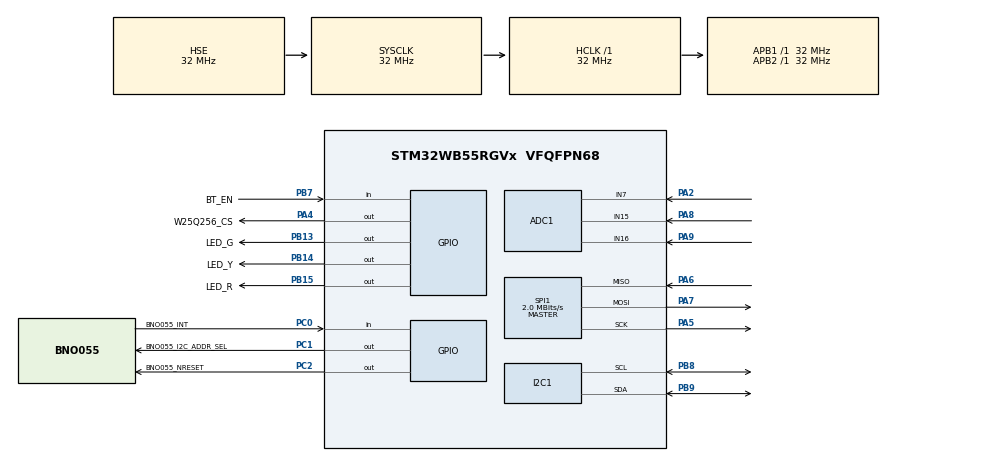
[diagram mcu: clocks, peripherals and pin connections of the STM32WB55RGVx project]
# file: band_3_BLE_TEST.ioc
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ADC1.Channel-2\#ChannelRegularConversion=ADC_CHANNEL_7
ADC1.NbrOfConversionFlag=1
ADC1.OffsetNumber-2\#ChannelRegularConversion=ADC_OFFSET_NONE
ADC1.Rank-2\#ChannelRegularConversion=1
ADC1.SamplingTime-2\#ChannelRegularConversion=ADC_SAMPLETIME_2CYCLES_5
ADC1.master=1
I2C1.Timing=0x00B07CB4
Mcu.Family=STM32WB
Mcu.Name=STM32WB55RGVx
Mcu.Package=VFQFPN68
NVIC.HSEM_IRQn=true\:0\:0\:false\:false\:true\:false\:true\:true
NVIC.IPCC_C1_RX_IRQn=true\:0\:0\:false\:false\:true\:true\:true\:true
NVIC.IPCC_C1_TX_IRQn=true\:0\:0\:false\:false\:true\:true\:true\:true
NVIC.PriorityGroup=NVIC_PRIORITYGROUP_4
NVIC.RTC_WKUP_IRQn=true\:0\:0\:false\:false\:true\:true\:true\:true
OSC_IN.Mode=HSE-External-Oscillator
OSC_IN.Signal=RCC_OSC_IN
OSC_OUT.Mode=HSE-External-Oscillator
OSC_OUT.Signal=RCC_OSC_OUT
PA11.Signal=USB_DM
PA12.Signal=USB_DP
PA13.Mode=Serial_Wire
PA13.Signal=SYS_JTMS-SWDIO
PA14.Mode=Serial_Wire
PA14.Signal=SYS_JTCK-SWCLK
PA2.Signal=ADCx_IN7
PA3.Signal=ADCx_IN8
PA4.GPIO_Label=W25Q256_CS
PA4.GPIO_Speed=GPIO_SPEED_FREQ_LOW
PA4.PinState=GPIO_PIN_SET
PA4.Signal=GPIO_Output
PA5.Mode=Full_Duplex_Master
PA5.Signal=SPI1_SCK
PA6.Mode=Full_Duplex_Master
PA6.Signal=SPI1_MISO
PA7.Mode=Full_Duplex_Master
PA7.Signal=SPI1_MOSI
PA8.Signal=ADCx_IN15
PA9.Signal=ADCx_IN16
PB13.GPIO_Label=LED_G
PB13.GPIO_Speed=GPIO_SPEED_FREQ_HIGH
PB13.PinState=GPIO_PIN_RESET
PB13.Signal=GPIO_Output
PB14.GPIO_Label=LED_Y
PB14.GPIO_Speed=GPIO_SPEED_FREQ_HIGH
PB14.PinState=GPIO_PIN_RESET
PB14.Signal=GPIO_Output
PB15.GPIO_Label=LED_R
PB15.GPIO_Speed=GPIO_SPEED_FREQ_HIGH
PB15.PinState=GPIO_PIN_SET
PB15.Signal=GPIO_Output
PB7.GPIO_Label=BT_EN
PB7.GPIO_PuPd=GPIO_NOPULL
PB7.Signal=GPIO_Input
PB8.Mode=I2C
PB8.Signal=I2C1_SCL
PB9.Mode=I2C
PB9.Signal=I2C1_SDA
PC0.GPIO_Label=BNO055_INT
PC0.Signal=GPIO_Input
PC1.GPIO_Label=BNO055_I2C_ADDR_SEL
PC1.Signal=GPIO_Output
PC12.Mode=SYS_WakeUp2
PC12.Signal=SYS_WKUP3
PC14-OSC32_IN.Mode=LSE-External-Oscillator
PC14-OSC32_IN.Signal=RCC_OSC32_IN
PC15-OSC32_OUT.Mode=LSE-External-Oscillator
PC15-OSC32_OUT.Signal=RCC_OSC32_OUT
PC2.GPIO_Label=BNO055_NRESET
PC2.PinState=GPIO_PIN_SET
PC2.Signal=GPIO_Output
ProjectManager.HeapSize=0x200
ProjectManager.StackSize=0x400
ProjectManager.TargetToolchain=MDK-ARM V5
RCC.ADCFreq_Value=48000000
RCC.AHBFreq_Value=32000000
RCC.APB1Freq_Value=32000000
RCC.APB1TimFreq_Value=32000000
RCC.APB2Freq_Value=32000000
RCC.APB2TimFreq_Value=32000000
RCC.APB3Freq_Value=16000000
RCC.CK48CLockSelection=RCC_USBCLKSOURCE_HSI48
RCC.CortexFreq_Value=32000000
RCC.HCLKFreq_Value=32000000
RCC.HSE_VALUE=32000000
RCC.HSI48_VALUE=48000000
RCC.HSI_VALUE=16000000
RCC.PLLN=32
RCC.PLLSAI1N=24
RCC.RFWKPClockSelection=RCC_RFWKPCLKSOURCE_LSE
RCC.RTCClockSelection=RCC_RTCCLKSOURCE_LSE
RCC.SYSCLKFreq_VALUE=32000000
RCC.SYSCLKSource=RCC_SYSCLKSOURCE_HSE
RCC.USBFreq_Value=48000000
RCC.VCOOutputFreq_Value=128000000
RF1.Mode=RF1_Activate
RF1.Signal=RF_RF1
SH.ADCx_IN15.0=ADC1_IN15,IN15-Single-Ended
SH.ADCx_IN16.0=ADC1_IN16,IN16-Single-Ended
SH.ADCx_IN7.0=ADC1_IN7,IN7-Single-Ended
SH.ADCx_IN8.0=ADC1_IN8
SPI1.BaudRatePrescaler=SPI_BAUDRATEPRESCALER_16
SPI1.CalculateBaudRate=2.0 MBits/s
SPI1.DataSize=SPI_DATASIZE_8BIT
SPI1.Direction=SPI_DIRECTION_2LINES
SPI1.Mode=SPI_MODE_MASTER
SPI1.VirtualType=VM_MASTER
STM32_WPAN.AD_TYPE_COMPLETE_LOCAL_NAME=band-STM32
STM32_WPAN.AD_TYPE_COMPLETE_LOCAL_NAME_LENGTH=11
STM32_WPAN.CFG_DEBUG_TRACE_UART=hw_uart1
STM32_WPAN.CFG_HW_USART1_ENABLED=1
STM32_WPAN.CUSTOM_P2P_SERVER=Enabled
STM32_WPAN.CUSTOM_TEMPLATE=Enabled
STM32_WPAN.INCLUDE_AD_TYPE_COMPLETE_LOCAL_NAME=1
STM32_WPAN.NUMBER_OF_SERVICES=1
STM32_WPAN.PAIRING_PARAMETERS=OFF
STM32_WPAN.SERVICE1_CHAR1_GATT_NOTIFY_ATTRIBUTE_WRITE=\ 
STM32_WPAN.SERVICE1_CHAR1_GATT_NOTIFY_READ_REQ_AND_WAIT_FOR_APPL_RESP=\ 
STM32_WPAN.SERVICE1_CHAR1_GATT_NOTIFY_WRITE_REQ_AND_WAIT_FOR_APPL_RESP=\ 
STM32_WPAN.SERVICE1_CHAR1_LONG_NAME=myCharWrite
STM32_WPAN.SERVICE1_CHAR1_PROP_READ=CHAR_PROP_READ
STM32_WPAN.SERVICE1_CHAR1_SHORT_NAME=myCharWrite
STM32_WPAN.SERVICE1_LONG_NAME=mySVC
STM32_WPAN.SERVICE1_SHORT_NAME=mySVC
VP_HSEM_VS_HSEM.Mode=HSEM_Activate
VP_IPCC_VS_IPCC.Mode=IPCC_Activate
VP_MEMORYMAP_VS_MEMORYMAP.Mode=CurAppReg
VP_RCC_LSE.Mode=CRS SYNC Source LSE
VP_RTC_VS_RTC_Activate.Mode=RTC_Enabled
VP_RTC_VS_RTC_WakeUp_intern.Mode=WakeUp
VP_SEQUENCER_VS_SEQUENCER.Mode=SEQUENCER_Enabled
VP_STM32_WPAN_VS_BLE_HOST.Mode=STM32_WPAN_Enabled
VP_TINY_LPM_VS_TINY_LPM.Mode=TINY_LPM_Enabled
board=custom

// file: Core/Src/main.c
/* USER CODE BEGIN Header */
/**
  ******************************************************************************
  * @file           : main.c
  * @brief          : Minimal BLE-only main with LED diagnostics (STM32WB)
  ******************************************************************************
  * @attention
  * Copyright (c) 2025 STMicroelectronics.
  * All rights reserved.
  * This software is licensed under terms that can be found in the LICENSE file
  * in the root directory of this software component.
  * If no LICENSE file comes with this software, it is provided AS-IS.
  ******************************************************************************
  */
/* USER CODE END Header */
#include "main.h"
#include "adc.h"
#include "i2c.h"
#include "ipcc.h"
#include "rf.h"
#include "rtc.h"
#include "spi.h"
#include "gpio.h"

/* USER CODE BEGIN Includes */
#include <stdbool.h>
/* USER CODE END Includes */

void SystemClock_Config(void);
void PeriphCommonClock_Config(void);

/* USER CODE BEGIN 0 */

// __attribute__((weak)) volatile bool cpu2_ready = false;

/* USER CODE END 0 */

int main(void)
{

  /* MCU Configuration--------------------------------------------------------*/

  /* Reset of all peripherals, Initializes the Flash interface and the Systick. */
  HAL_Init();
  /* Config code for STM32_WPAN (HSE Tuning must be done before system clock configuration) */
	MX_GPIO_Init();
	MX_APPE_Config();

  /* Configure the system clock */

  SystemClock_Config();

  /* Configure the peripherals common clocks */
  PeriphCommonClock_Config();

	MX_APPE_Init();

  /* IPCC initialisation */
  MX_IPCC_Init();

  /* Initialize all configured peripherals */

  MX_ADC1_Init();
  MX_I2C1_Init();
  MX_SPI1_Init();
  MX_RTC_Init();
  MX_RF_Init();
  /* USER CODE BEGIN 2 */
  /* 这里你可以点亮一个绿灯表示 CPU1 已经跑起来了，比如：
   * HAL_GPIO_WritePin(GPIOB, LED_G_Pin, GPIO_PIN_SET);
   */
  /* USER CODE END 2 */

  /* Init code for STM32_WPAN */
  MX_APPE_Init();

  /* Infinite loop */
  /* USER CODE BEGIN WHILE */
  while (1)
  {
    MX_APPE_Process();
	/*	if(hci_le_set_advertising_enable(0x01) == BLE_STATUS_SUCCESS){
    HAL_GPIO_TogglePin(GPIOB, LED_G_Pin);
		HAL_Delay(5000);}*/
    /* USER CODE BEGIN 3 */
    /* <<< 修改点 3：简单心跳灯，证明主循环在跑。
     * 比如每 500ms 翻转一次绿灯（按你实际引脚改）：

#if 1
    static uint32_t lastToggle = 0;
    if (HAL_GetTick() - lastToggle > 500) {
      lastToggle = HAL_GetTick();
      HAL_GPIO_TogglePin(GPIOB, LED_G_Pin);
    }
#endif*/
    /* USER CODE END 3 */
  }
    /* USER CODE END WHILE */
    MX_APPE_Process();

    /* USER CODE BEGIN 3 */
    /* <<< 修改点 3：简单心跳灯，证明主循环在跑。
     * 比如每 500ms 翻转一次绿灯（按你实际引脚改）：

#if 1
    static uint32_t lastToggle = 0;
    if (HAL_GetTick() - lastToggle > 500) {
      lastToggle = HAL_GetTick();
      HAL_GPIO_TogglePin(GPIOB, LED_G_Pin);
    }
#endif*/
  /* USER CODE END 3 */
}

void SystemClock_Config(void)
{
  RCC_OscInitTypeDef RCC_OscInitStruct = {0};
  RCC_ClkInitTypeDef RCC_ClkInitStruct = {0};
  RCC_CRSInitTypeDef RCC_CRSInitStruct = {0};

  /** Macro to configure the PLL multiplication factor
  */
  __HAL_RCC_PLL_PLLM_CONFIG(RCC_PLLM_DIV1);

  /** Macro to configure the PLL clock source
  */
  __HAL_RCC_PLL_PLLSOURCE_CONFIG(RCC_PLLSOURCE_MSI);

  /** Configure LSE Drive Capability
  */
  HAL_PWR_EnableBkUpAccess();
  __HAL_RCC_LSEDRIVE_CONFIG(RCC_LSEDRIVE_MEDIUMHIGH);

  /** Configure the main internal regulator output voltage
  */
  __HAL_PWR_VOLTAGESCALING_CONFIG(PWR_REGULATOR_VOLTAGE_SCALE1);

  /** Initializes the RCC Oscillators according to the specified parameters
  * in the RCC_OscInitTypeDef structure.
  */
  RCC_OscInitStruct.OscillatorType = RCC_OSCILLATORTYPE_HSI|RCC_OSCILLATORTYPE_HSE
                              |RCC_OSCILLATORTYPE_LSE|RCC_OSCILLATORTYPE_MSI;
  RCC_OscInitStruct.HSEState = RCC_HSE_ON;
  RCC_OscInitStruct.LSEState = RCC_LSE_ON;
  RCC_OscInitStruct.HSIState = RCC_HSI_ON;
  RCC_OscInitStruct.MSIState = RCC_MSI_ON;
  RCC_OscInitStruct.HSICalibrationValue = RCC_HSICALIBRATION_DEFAULT;
  RCC_OscInitStruct.MSICalibrationValue = RCC_MSICALIBRATION_DEFAULT;
  RCC_OscInitStruct.MSIClockRange = RCC_MSIRANGE_6;
  RCC_OscInitStruct.PLL.PLLState = RCC_PLL_NONE;
  if (HAL_RCC_OscConfig(&RCC_OscInitStruct) != HAL_OK)
  {
    Error_Handler();
  }

  /** Configure the SYSCLKSource, HCLK, PCLK1 and PCLK2 clocks dividers
  */
  RCC_ClkInitStruct.ClockType = RCC_CLOCKTYPE_HCLK4|RCC_CLOCKTYPE_HCLK2
                              |RCC_CLOCKTYPE_HCLK|RCC_CLOCKTYPE_SYSCLK
                              |RCC_CLOCKTYPE_PCLK1|RCC_CLOCKTYPE_PCLK2;
  RCC_ClkInitStruct.SYSCLKSource = RCC_SYSCLKSOURCE_HSE;
  RCC_ClkInitStruct.AHBCLKDivider = RCC_SYSCLK_DIV1;
  RCC_ClkInitStruct.APB1CLKDivider = RCC_HCLK_DIV1;
  RCC_ClkInitStruct.APB2CLKDivider = RCC_HCLK_DIV1;
  RCC_ClkInitStruct.AHBCLK2Divider = RCC_SYSCLK_DIV1;
  RCC_ClkInitStruct.AHBCLK4Divider = RCC_SYSCLK_DIV1;

  if (HAL_RCC_ClockConfig(&RCC_ClkInitStruct, FLASH_LATENCY_1) != HAL_OK)
  {
    Error_Handler();
  }

  /** Enable the SYSCFG APB clock
  */
  __HAL_RCC_CRS_CLK_ENABLE();

  /** Configures CRS
  */
  RCC_CRSInitStruct.Prescaler = RCC_CRS_SYNC_DIV1;
  RCC_CRSInitStruct.Source = RCC_CRS_SYNC_SOURCE_LSE;
  RCC_CRSInitStruct.Polarity = RCC_CRS_SYNC_POLARITY_RISING;
  RCC_CRSInitStruct.ReloadValue = __HAL_RCC_CRS_RELOADVALUE_CALCULATE(48000000,32768);
  RCC_CRSInitStruct.ErrorLimitValue = 34;
  RCC_CRSInitStruct.HSI48CalibrationValue = 32;

  HAL_RCCEx_CRSConfig(&RCC_CRSInitStruct);
}

void PeriphCommonClock_Config(void)
{
  RCC_PeriphCLKInitTypeDef PeriphClkInitStruct = {0};

  /** Initializes the peripherals clock
  */
  PeriphClkInitStruct.PeriphClockSelection = RCC_PERIPHCLK_SMPS|RCC_PERIPHCLK_RFWAKEUP;
  PeriphClkInitStruct.RFWakeUpClockSelection = RCC_RFWKPCLKSOURCE_LSE;
  PeriphClkInitStruct.SmpsClockSelection = RCC_SMPSCLKSOURCE_HSI;
  PeriphClkInitStruct.SmpsDivSelection = RCC_SMPSCLKDIV_RANGE1;

  if (HAL_RCCEx_PeriphCLKConfig(&PeriphClkInitStruct) != HAL_OK)
  {
    Error_Handler();
  }
}

/* USER CODE BEGIN 4 */
/* 你原来手动重写 MX_GPIO_Init() 的那段先保持关掉（#if 0），
 * 尽量用 CubeMX 自动生成的 GPIO 初始化，确保 LED_R/LED_G 已经配置为输出。
 */
/* USER CODE END 4 */

void Error_Handler(void)
{
  /* USER CODE BEGIN Error_Handler_Debug */
  __disable_irq();
  while (1)
  {
    /* 这里你也可以加一个红灯快速闪烁，表示系统出了严重错误 */
    // HAL_GPIO_TogglePin(GPIOB, LED_R_Pin);
    // HAL_Delay(100);
  }
  /* USER CODE END Error_Handler_Debug */
}
#ifdef USE_FULL_ASSERT
/**
  * @brief  Reports the name of the source file and the source line number
  *         where the assert_param error has occurred.
  * @param  file: pointer to the source file name
  * @param  line: assert_param error line source number
  * @retval None
  */
void assert_failed(uint8_t *file, uint32_t line)
{
  /* USER CODE BEGIN 6 */
  (void)file;
  (void)line;
  /* USER CODE END 6 */
}
#endif /* USE_FULL_ASSERT */
